# 3067M register map
File version: 1.0
Registers are 32-bit, access per field, reset 0x0 unless marked. A register's access mark holds for its fields unless they carry their own. Offsets are from the block's base; [hi:lo] are bit positions.

## IWDG — IWDG peripheral interface
Base 0x14401000
0x00 IWDG_LOAD 12-bit reset 0xFFF — IWDG_LOAD为计数初值寄存器。
  [31:12] reserved ro — 保留。
  [11:0] iwdg_load rw — 计数初值，IWDG从该值开始减计数。受IWDG_KEY[iwdg_key]的写权限控制。软件须读IWDG_STATUS[load_update]为0后，才可以写。推荐配置大于2。
0x04 IWDG_VALUE 12-bit ro reset 0xFFF — IWDG_VALUE为计数器当前值寄存器。
  [31:12] reserved — 保留。
  [11:0] iwdg_value — WatchDog计数器当前值，读出值延后于实际计数器的当前值约50µs。
0x08 IWDG_WINDOW 12-bit reset 0xFFF — IWDG_WINDOW为窗口值寄存器。
  [31:12] reserved ro — 保留。
  [11:0] iwdg_window rw — 窗口值。受IWDG_KEY[iwdg_key]的写权限控制。软件须读IWDG_STATUS[window_update]为0后，才可以写。 禁止大于IWDG_LOAD[iwdg_load]寄存器，否则会产生预期之外的动作。
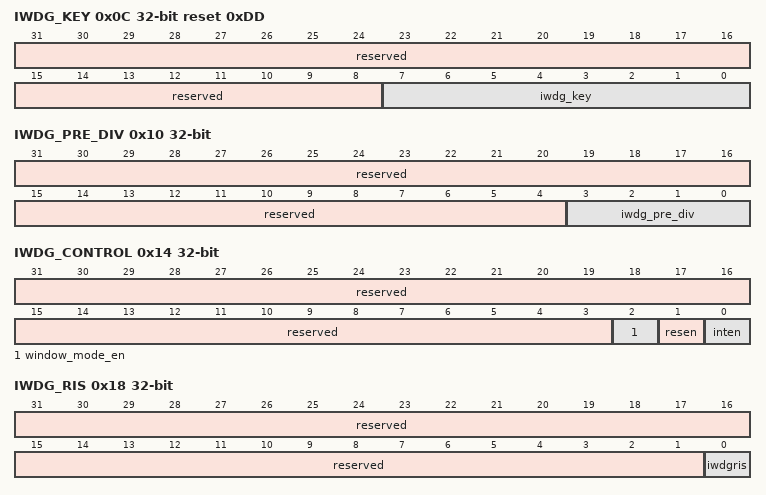
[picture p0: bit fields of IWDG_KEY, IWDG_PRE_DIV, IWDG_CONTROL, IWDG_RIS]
0x0C IWDG_KEY reset 0xDD — IWDG_KEY为指令字寄存器。
  [31:8] reserved ro — 保留。
  [7:0] iwdg_key rw — 指令字有多种功能，软件须读IWDG_STATUS[key_update]为0后，才可以写。 写入0xAA：WatchDog从寄存器IWDG_LOAD中重新载入初值计数（喂狗），并可清除WatchDog的中断。 写入0x55：使能写权限； 写入其他值：禁止写权限； 写入0xCC：可开启IWDG； 回读0xDD：表示IWDG处于关闭状态。 IWDG一旦被使能，软件无法配置关闭，只能被复位关闭。
0x10 IWDG_PRE_DIV access not given — IWDG_PRE_DIV为预分频寄存器。
  [31:4] reserved ro — 保留。
  [3:0] iwdg_pre_div — 工作时钟的2的幂次分频。受IWDG_KEY[iwdg_key]的写权限控制。软件须读IWDG_STATUS[pre_div_update]为0后，才可以写。 0x0：4分频； 0x1：8分频； 0x2：16分频： 0x3：32分频； 0x4：64分频； 0x5：128分频； 0x6：256分频； 0x7：512分频； 0x8：1024分频； 其他：1024分频。
0x14 IWDG_CONTROL — IWDG_CONTROL为控制寄存器。
  [31:3] reserved ro — 保留。
  [2] window_mode_en rw — WatchDog窗口模式使能。受IWDG_KEY[iwdg_key]的写权限控制。软件须读IWDG_STATUS[control_update]为0后，才可以写。 0：禁止； 1：使能。 当禁止窗口模式时，无需设置iwdg_window，中断固定在iwdg_load/2处产生，此时在任意时刻喂狗均不会触发复位信号，复位信号只有在计数值为0且未清除中断时才会产生。 当使能窗口模式时，iwdg_window值生效，中断在计数器值等于窗口值时产生，在窗口值之外喂狗会产生复位信号，在计数为0且未清除中断时也会产生复位信号。
  [1] resen rw — WatchDog复位信号输出使能。受IWDG_KEY[iwdg_key]的写权限控制。软件须读IWDG_STATUS[control_update]为0后，才可以写。 0：禁止； 1：使能。
  [0] inten rw — WatchDog中断信号输出使能。受IWDG_KEY[iwdg_key]的写权限控制。软件须读IWDG_STATUS[control_update]为0后，才可以写。 0：禁止iwdgmis产生； 1：使能iwdgmis。
0x18 IWDG_RIS ro — IWDG_RIS为原始中断标志寄存器。
  [31:1] reserved — 保留。
  [0] iwdgris — WatchDog原始中断状态。 0：未产生中断； 1：已产生中断。 IWDG_CONTROL[window_mode_en]为0时，计数值等于iwdg_load/2时产生中断。 IWDG_CONTROL[window_mode_en]为1时，计数值等于iwdg_window时产生中断。
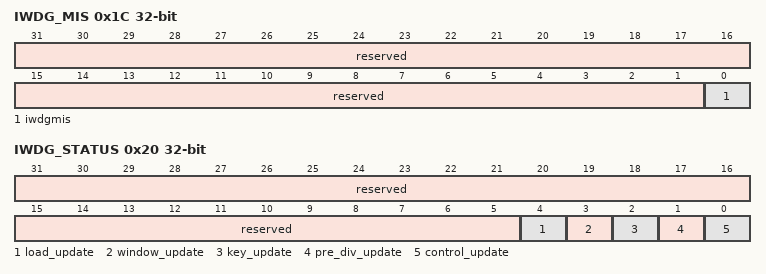
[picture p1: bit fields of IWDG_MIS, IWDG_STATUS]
0x1C IWDG_MIS ro — IWDG_MIS为屏蔽后中断标志寄存器。
  [31:1] reserved — 保留。
  [0] iwdgmis — WatchDog屏蔽后的中断状态。 0：未产生中断或者中断被屏蔽； 1：已产生中断。
0x20 IWDG_STATUS ro — IWDG_STATUS为状态寄存器。
  [31:5] reserved — 保留。
  [4] load_update — IWDG_LOAD寄存器更新状态。 0：硬件更新完毕后，自动清零； 1：软件写IWDG_LOAD寄存器，load_update置1。只有当load_update为0时，软件才能更新IWDG_LOAD寄存器。
  [3] window_update — IWDG_WINDOW寄存器更新状态。 0：硬件更新完毕后，自动清零； 1：软件写IWDG_WINDOW寄存器，置1。只有当window_update为0时，软件才能更新IWDG_WINDOW寄存器。
  [2] key_update — IWDG_KEY寄存器更新状态。 0：硬件更新完毕后，自动清零； 1：软件写IWDG_KEY寄存器，置1。只有当key_update为0时，软件才能更新IWDG_KEY寄存器。
  [1] pre_div_update — IWDG_PRE_DIV寄存器更新状态。 0：硬件更新完毕后，自动清零； 1：软件写IWDG_PRE_DIV寄存器，置1。只有当pre_div_update为0时，软件才能更新IWDG_PRE_DIV寄存器。
  [0] control_update — IWDG_CONTROL寄存器更新状态。 0：硬件更新完毕后，自动清零； 1：软件写IWDG_CONTROL寄存器，置1。只有当control_update为0时，软件才能更新IWDG_CONTROL寄存器。

## ACMP0 — ACMP peripheral interface
Base 0x18300000
Same registers: ACMP1 0x18301000, ACMP2 0x18302000, ACMP3 0x18303000, ACMP4 0x18304000, ACMP5 0x18305000, ACMP6 0x18306000, ACMP7 0x18307000
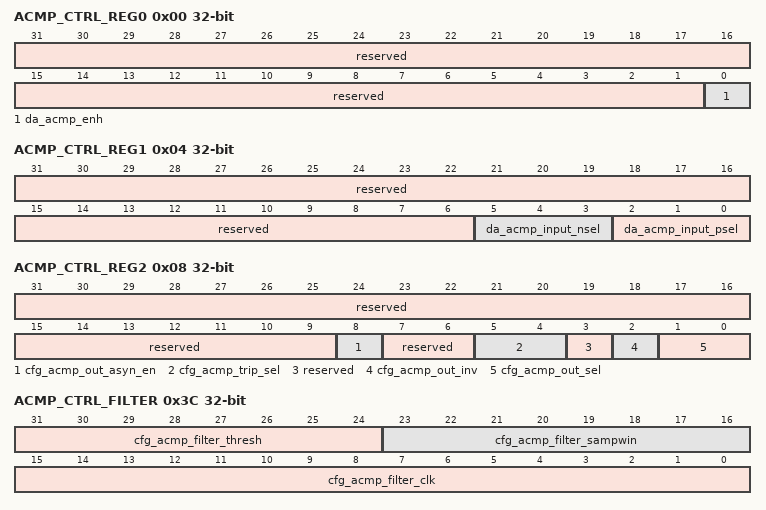
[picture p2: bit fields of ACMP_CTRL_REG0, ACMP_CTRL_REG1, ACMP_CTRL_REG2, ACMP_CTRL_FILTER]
0x00 ACMP_CTRL_REG0 — ACMP控制寄存器0。
  [31:1] reserved ro — 保留。
  [0] da_acmp_enh rw — 比较器使能信号。 0：关闭； 1：使能。
0x04 ACMP_CTRL_REG1 — ACMP控制寄存器1。
  [31:6] reserved ro — 保留。
  [5:3] da_acmp_input_nsel rw — 比较器输入通道N端选通。 000：VINN0； 001：VINN1； 010：VINN2； 011：VINN3； 100：VINN4； 101：VINN5； 其他：未使用。
  [2:0] da_acmp_input_psel rw — 比较器输入通道P端选通。 000：VINP0； 001：VINP1； 010：VINP2； 011：VINP3； 100：VINP4； 101：VINP5； 其他：未使用。
0x08 ACMP_CTRL_REG2 — ACMP控制寄存器2。
  [31:9] reserved ro — 保留。
  [8] cfg_acmp_out_asyn_en rw — 异步路径使能。 0：不使能； 1：使能。当ACMP_CTRL_REG2[cfg_acmp_out_sel]==10时，异步比较结果与锁存后的滤波结果做或操作。
  [7:6] reserved rw — 保留。
  [5:4] cfg_acmp_trip_sel rw — ACMP_TRIP来源选择。 00：异步比较结果，ACMP_RSLT_REG[cmp_ana_rslt]； 01：滤波结果，ACMP_RSLT_REG[cmp_filter_rslt]； 10：锁存后的滤波结果，ACMP_RSLT_REG[cmp_latch_rslt]； 11：同步比较结果，ACMP_RSLT_REG[cmp_sync_rslt]。
  [3] reserved rw — 保留。
  [2] cfg_acmp_out_inv rw — 比较器输出是否取反。 0：不取反； 1：取反。
  [1:0] cfg_acmp_out_sel rw — ACMP_OUT来源选择。 00：异步比较结果，ACMP_RSLT_REG[cmp_ana_rslt]； 01：滤波结果，ACMP_RSLT_REG[cmp_filter_rslt]； 10：锁存后的滤波结果，ACMP_RSLT_REG[cmp_latch_rslt]； 11：同步比较结果，ACMP_RSLT_REG[cmp_sync_rslt]。
0x3C ACMP_CTRL_FILTER — ACMP滤波分频寄存器。
  [31:24] cfg_acmp_filter_thresh ro — 滤波多数表决阈值。至少需要cfg_acmp_filter_thresh个相反的值出现在采样窗口内，输出才会改变。 注意：多数表决阈值需要大于采样窗口大小的一半。
  [23:16] cfg_acmp_filter_sampwin rw — 滤波采样窗口大小=cfg_acmp_filter_sampwin。
  [15:0] cfg_acmp_filter_clk rw — 滤波采样间隔周期=cfg_acmp_filter_clk+1。
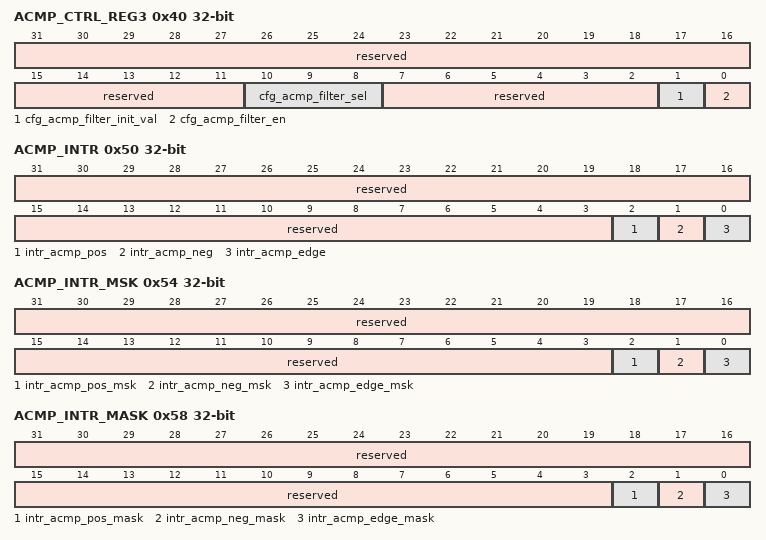
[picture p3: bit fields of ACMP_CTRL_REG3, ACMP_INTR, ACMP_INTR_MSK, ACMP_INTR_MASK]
0x40 ACMP_CTRL_REG3 — ACMP滤波控制寄存器。
  [31:11] reserved ro — 保留。
  [10:8] cfg_acmp_filter_sel rw — 滤波输入选择。 000：内部比较器； 001：外部比较器1； 010：外部比较器2； 011：外部比较器3； … 111：外部比较器7。
  [7:2] reserved rw — 保留。
  [1] cfg_acmp_filter_init_val rw — 滤波初始值。
  [0] cfg_acmp_filter_en rw — 比较器滤波使能。 0：关闭； 1：使能。
0x44 ACMP_CTRL_REG4 reset 0x1000000 — ACMP屏蔽控制寄存器。
  [31:17] reserved ro — 保留。
  [16] cfg_acmp_blk_win rw — 软件配置屏蔽窗口。 0：屏蔽； 1：不屏蔽。
  [15:13] reserved rw — 保留。
  [12:8] cfg_acmp_blk_sel rw — 比较器屏蔽窗口选择。 0x0：软件配置屏蔽窗口； 0x1：APT0输出屏蔽窗口； 0x2：APT1输出屏蔽窗口； 0x3：APT2输出屏蔽窗口； 0x4：APT3输出屏蔽窗口； … 0x10：APT15输出屏蔽窗口； 其他：0。
  [7:1] reserved rw — 保留。
  [16:0] cfg_acmp_blk_en rw — 比较器屏蔽使能。 0：关闭； 1：使能。
0x50 ACMP_INTR — ACMP中断原始状态寄存器。
  [31:3] reserved ro — 保留。
  [2] intr_acmp_pos INT_RW1C — 比较结果上升沿中断状态。
  [1] intr_acmp_neg INT_RW1C — 比较结果下降沿中断状态。
  [0] intr_acmp_edge INT_RW1C — 比较结果翻转沿中断状态。
0x54 ACMP_INTR_MSK ro — ACMP中断屏蔽后状态寄存器。
  [31:3] reserved — 保留。
  [2] intr_acmp_pos_msk — 比较结果上升沿屏蔽后中断状态。
  [1] intr_acmp_neg_msk — 比较结果下降沿屏蔽后中断状态。
  [0] intr_acmp_edge_msk — 比较结果翻转沿屏蔽后中断状态。
0x58 ACMP_INTR_MASK — ACMP中断屏蔽寄存器。
  [31:3] reserved ro — 保留。
  [2] intr_acmp_pos_mask rw — 比较结果上升沿中断屏蔽寄存器。 0：屏蔽中断； 1：不屏蔽。
  [1] intr_acmp_neg_mask rw — 比较结果下降沿中断屏蔽寄存器。 0：屏蔽中断； 1：不屏蔽。
  [0] intr_acmp_edge_mask rw — 比较结果翻转沿中断屏蔽寄存器。 0：屏蔽中断； 1：不屏蔽。
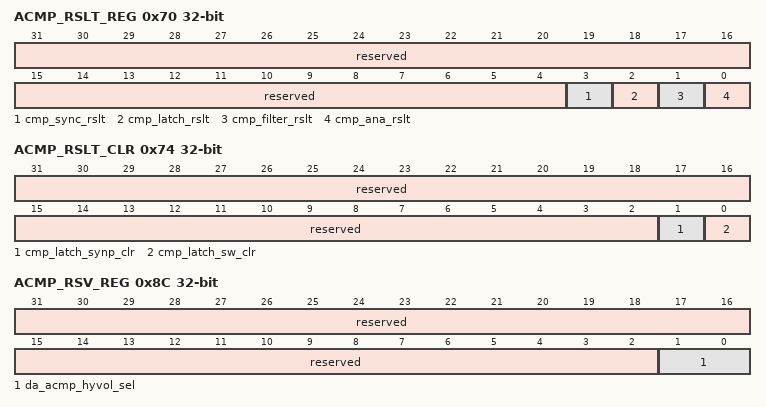
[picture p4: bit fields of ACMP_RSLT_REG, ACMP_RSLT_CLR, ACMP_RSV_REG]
0x70 ACMP_RSLT_REG — ACMP结果寄存器。
  [31:4] reserved ro — 保留。
  [3] cmp_sync_rslt ro — 同步比较结果。
  [2] cmp_latch_rslt ro — 锁存后的滤波结果。
  [1] cmp_filter_rslt ro — 滤波结果。
  [0] cmp_ana_rslt rw — 异步比较结果。
0x74 ACMP_RSLT_CLR — ACMP结果清除寄存器。
  [31:2] reserved ro — 保留。
  [1] cmp_latch_synp_clr rw — APTSYNCP清除滤波结果ACMP_RSLT_REG[cmp_filter_rslt]和锁存后的滤波结果ACMP_RSLT_REG[cmp_latch_rslt]。 0：不使能； 1：使能。
  [0] cmp_latch_sw_clr W1_PULSE — 软件清除滤波结果ACMP_RSLT_REG[cmp_filter_rslt]和锁存后的滤波结果ACMP_RSLT_REG[cmp_latch_rslt]。 0：无效果； 1：产生脉冲，复位滤波结果和锁存后的滤波结果。
0x8C ACMP_RSV_REG — ACMP预留寄存器。
  [31:2] reserved ro — 保留。
  [1:0] da_acmp_hyvol_sel rw — 迟滞电压选择。 00：无迟滞功能； 10：20mV； 11：30mV； 其他：保留。
